# STM32F0x8 register map
File version: 1.3
CPU: CM0 r0p0, little endian, no MPU, no FPU, 3 interrupt priority bits
Registers are 32-bit, read-write, reset 0x0 unless marked. A register's access mark holds for its fields unless they carry their own. Offsets are from the block's base; [hi:lo] are bit positions; {n}, {i} and the like mark numbered series.

## RTC — Real-time clock
Base 0x40002800
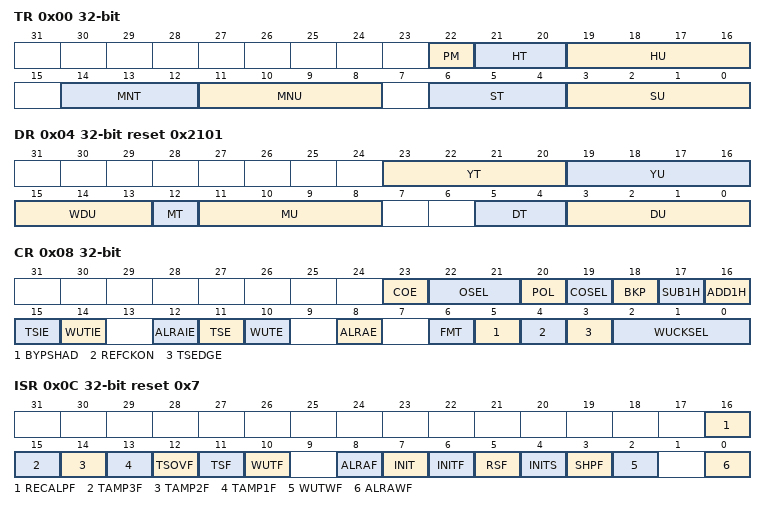
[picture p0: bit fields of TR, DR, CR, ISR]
0x00 TR — time register
  [22] PM — AM/PM notation
  [21:20] HT — Hour tens in BCD format
  [19:16] HU — Hour units in BCD format
  [14:12] MNT — Minute tens in BCD format
  [11:8] MNU — Minute units in BCD format
  [6:4] ST — Second tens in BCD format
  [3:0] SU — Second units in BCD format
0x04 DR reset 0x2101 — date register
  [23:20] YT — Year tens in BCD format
  [19:16] YU — Year units in BCD format
  [15:13] WDU — Week day units
  [12] MT — Month tens in BCD format
  [11:8] MU — Month units in BCD format
  [5:4] DT — Date tens in BCD format
  [3:0] DU — Date units in BCD format
0x08 CR access per field — control register
  [23] COE rw — Calibration output enable
  [22:21] OSEL rw — Output selection
  [20] POL rw — Output polarity
  [19] COSEL rw — Calibration output selection
  [18] BKP rw — Backup
  [17] SUB1H wo — Subtract 1 hour (winter time change)
  [16] ADD1H wo — Add 1 hour (summer time change)
  [15] TSIE rw — Time-stamp interrupt enable
  [14] WUTIE rw — Wakeup timer interrupt enable
  [12] ALRAIE rw — Alarm A interrupt enable
  [11] TSE rw — timestamp enable
  [10] WUTE rw — Wakeup timer enable
  [8] ALRAE rw — Alarm A enable
  [6] FMT rw — Hour format
  [5] BYPSHAD rw — Bypass the shadow registers
  [4] REFCKON rw — RTC_REFIN reference clock detection enable (50 or 60 Hz)
  [3] TSEDGE rw — Time-stamp event active edge
  [2:0] WUCKSEL rw — Wakeup clock selection
0x0C ISR access per field reset 0x7 — initialization and status register
  [16] RECALPF ro — Recalibration pending Flag
  [15] TAMP3F rw — RTC_TAMP3 detection flag
  [14] TAMP2F rw — RTC_TAMP2 detection flag
  [13] TAMP1F rw — RTC_TAMP1 detection flag
  [12] TSOVF rw — Time-stamp overflow flag
  [11] TSF rw — Time-stamp flag
  [10] WUTF rw — Wakeup timer flag
  [8] ALRAF rw — Alarm A flag
  [7] INIT rw — Initialization mode
  [6] INITF ro — Initialization flag
  [5] RSF rw — Registers synchronization flag
  [4] INITS ro — Initialization status flag
  [3] SHPF rw — Shift operation pending
  [2] WUTWF ro — Wakeup timer write flag
  [0] ALRAWF ro — Alarm A write flag
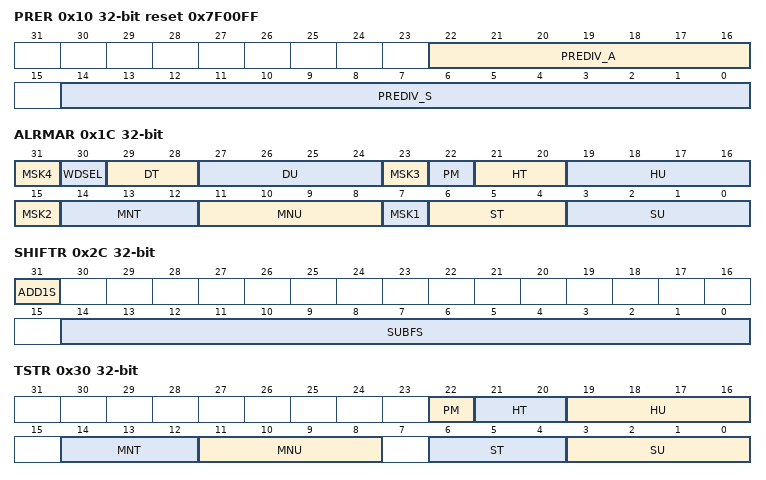
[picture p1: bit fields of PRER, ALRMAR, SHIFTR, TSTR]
0x10 PRER reset 0x7F00FF — prescaler register
  [22:16] PREDIV_A — Asynchronous prescaler factor
  [14:0] PREDIV_S — Synchronous prescaler factor
0x14 WUTR reset 0xFFFF — wakeup timer register
  [15:0] WUT — Wakeup auto-reload value bits
0x1C ALRMAR — alarm A register
  [31] MSK4 — Alarm A date mask
  [30] WDSEL — Week day selection
  [29:28] DT — Date tens in BCD format.
  [27:24] DU — Date units or day in BCD format.
  [23] MSK3 — Alarm A hours mask
  [22] PM — AM/PM notation
  [21:20] HT — Hour tens in BCD format.
  [19:16] HU — Hour units in BCD format.
  [15] MSK2 — Alarm A minutes mask
  [14:12] MNT — Minute tens in BCD format.
  [11:8] MNU — Minute units in BCD format.
  [7] MSK1 — Alarm A seconds mask
  [6:4] ST — Second tens in BCD format.
  [3:0] SU — Second units in BCD format.
0x24 WPR wo — write protection register
  [7:0] KEY — Write protection key
0x28 SSR ro — sub second register
  [15:0] SS — Sub second value
0x2C SHIFTR wo — shift control register
  [31] ADD1S — Add one second
  [14:0] SUBFS — Subtract a fraction of a second
0x30 TSTR ro — timestamp time register
  [22] PM — AM/PM notation
  [21:20] HT — Hour tens in BCD format.
  [19:16] HU — Hour units in BCD format.
  [14:12] MNT — Minute tens in BCD format.
  [11:8] MNU — Minute units in BCD format.
  [6:4] ST — Second tens in BCD format.
  [3:0] SU — Second units in BCD format.
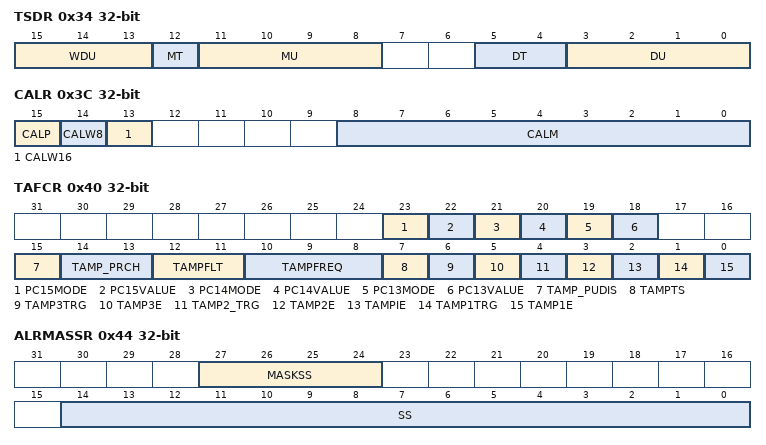
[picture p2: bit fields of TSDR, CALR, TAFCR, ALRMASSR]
0x34 TSDR ro — timestamp date register
  [15:13] WDU — Week day units
  [12] MT — Month tens in BCD format
  [11:8] MU — Month units in BCD format
  [5:4] DT — Date tens in BCD format
  [3:0] DU — Date units in BCD format
0x38 TSSSR ro — time-stamp sub second register
  [15:0] SS — Sub second value
0x3C CALR — calibration register
  [15] CALP — Increase frequency of RTC by 488.5 ppm
  [14] CALW8 — Use an 8-second calibration cycle period
  [13] CALW16 — Use a 16-second calibration cycle period
  [8:0] CALM — Calibration minus
0x40 TAFCR — tamper and alternate function configuration register
  [23] PC15MODE
  [22] PC15VALUE
  [21] PC14MODE
  [20] PC14VALUE
  [19] PC13MODE
  [18] PC13VALUE — RTC_ALARM output type/PC13 value
  [15] TAMP_PUDIS — RTC_TAMPx pull-up disable
  [14:13] TAMP_PRCH — RTC_TAMPx precharge duration
  [12:11] TAMPFLT — RTC_TAMPx filter count
  [10:8] TAMPFREQ — Tamper sampling frequency
  [7] TAMPTS — Activate timestamp on tamper detection event
  [6] TAMP3TRG — Active level for RTC_TAMP3 input
  [5] TAMP3E — RTC_TAMP3 detection enable
  [4] TAMP2_TRG — Active level for RTC_TAMP2 input
  [3] TAMP2E — RTC_TAMP2 input detection enable
  [2] TAMPIE — Tamper interrupt enable
  [1] TAMP1TRG — Active level for RTC_TAMP1 input
  [0] TAMP1E — RTC_TAMP1 input detection enable
0x44 ALRMASSR — alarm A sub second register
  [27:24] MASKSS — Mask the most-significant bits starting at this bit
  [14:0] SS — Sub seconds value
{0x50+4i} BKP{i}R (i=0..4) — backup register
  [31:0] BKP
